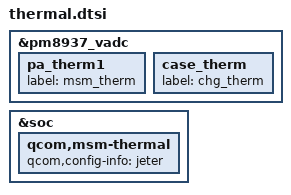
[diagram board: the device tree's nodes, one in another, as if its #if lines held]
&pm8937_vadc {
	pa_therm1 {
		label = "msm_therm";
	};

	case_therm {
		label = "chg_therm";
	};
};

&soc{
	qcom,msm-thermal {
#if defined(DEVICE_JETER)
		qcom,config-info = "jeter";
#else
		qcom,config-info = "aljeter";
#endif
	};
};
